AUTOSAR XML (schema 4-2-2)
package /STELLANTIS/EPT/ASWCs
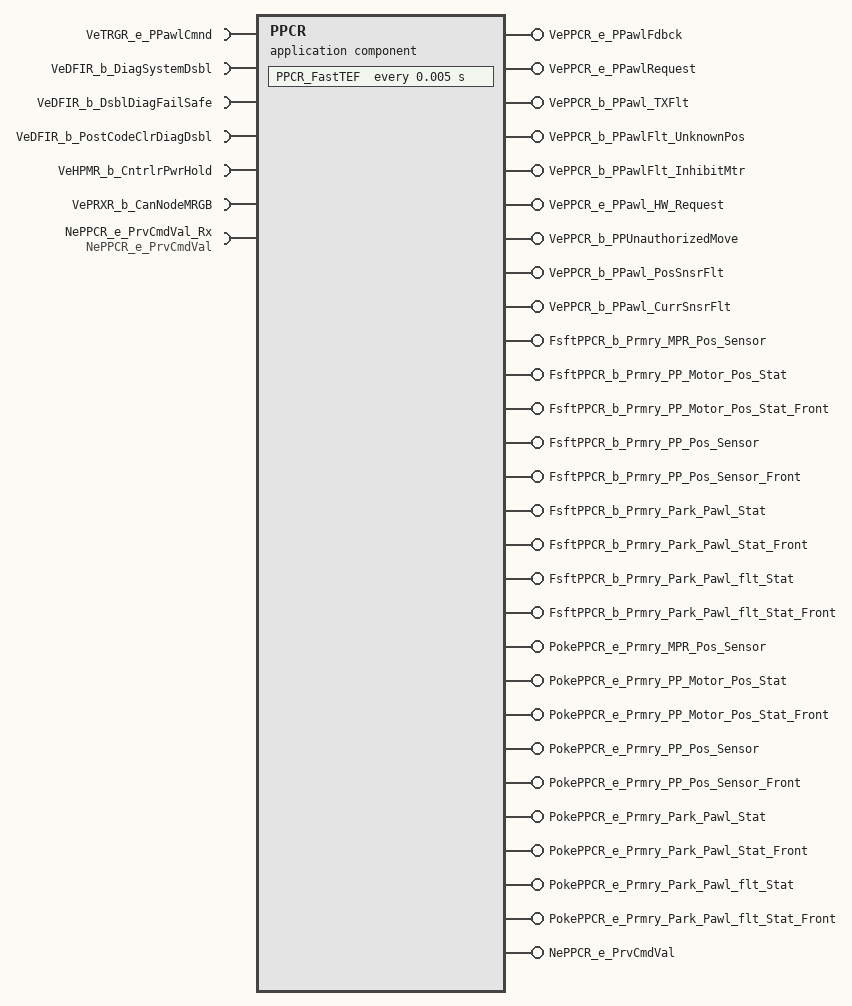
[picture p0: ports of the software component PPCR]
  application sw component type PPCR
    6 x require port:
      VeTRGR_e_PPawlCmnd: variation-point={short-label=vpVeTRGR_e_PPawlCmnd, sw-syscond=1}, nonqueued-receiver-com-spec{data-element=Value, init-value=CeTRGR_e_PPawlIdle}, required-interface=VeTRGR_e_PPawlCmnd
      VeDFIR_b_DiagSystemDsbl: variation-point={short-label=vpVeDFIR_b_DiagSystemDsbl, sw-syscond=1}, nonqueued-receiver-com-spec{data-element=Value, init-value=0}, required-interface=VeDFIR_b_DiagSystemDsbl
      VeDFIR_b_DsblDiagFailSafe: variation-point={short-label=vpVeDFIR_b_DsblDiagFailSafe, sw-syscond=1}, nonqueued-receiver-com-spec{data-element=Value, init-value=0}, required-interface=VeDFIR_b_DsblDiagFailSafe
      VeDFIR_b_PostCodeClrDiagDsbl: variation-point={short-label=vpVeDFIR_b_PostCodeClrDiagDsbl, sw-syscond=1}, nonqueued-receiver-com-spec{data-element=Value, init-value=0}, required-interface=VeDFIR_b_PostCodeClrDiagDsbl
      VeHPMR_b_CntrlrPwrHold: variation-point={short-label=vpVeHPMR_b_CntrlrPwrHold, sw-syscond=1}, nonqueued-receiver-com-spec{data-element=Value, init-value=0}, required-interface=VeHPMR_b_CntrlrPwrHold
      VePRXR_b_CanNodeMRGB: variation-point={short-label=vpVePRXR_b_CanNodeMRGB, sw-syscond=1}, nonqueued-receiver-com-spec{data-element=Value, init-value=0}, required-interface=VePRXR_b_CanNodeMRGB
    27 x provide port:
      VePPCR_e_PPawlFdbck: nonqueued-sender-com-spec{data-element=Value, init-value=CePPCR_e_PPAWL_UNKNOWN_Position}, provided-interface=VePPCR_e_PPawlFdbck
      VePPCR_e_PPawlRequest: nonqueued-sender-com-spec{data-element=Value, init-value=CePPCR_e_PPAWL_UNKNOWN_Request}, provided-interface=VePPCR_e_PPawlRequest
      VePPCR_b_PPawl_TXFlt: nonqueued-sender-com-spec{data-element=Value, init-value=0}, provided-interface=VePPCR_b_PPawl_TXFlt
      VePPCR_b_PPawlFlt_UnknownPos: nonqueued-sender-com-spec{data-element=Value, init-value=0}, provided-interface=VePPCR_b_PPawlFlt_UnknownPos
      VePPCR_b_PPawlFlt_InhibitMtr: nonqueued-sender-com-spec{data-element=Value, init-value=0}, provided-interface=VePPCR_b_PPawlFlt_InhibitMtr
      VePPCR_e_PPawl_HW_Request: nonqueued-sender-com-spec{data-element=Value, init-value=CePPCR_e_Req_No_Req}, provided-interface=VePPCR_e_PPawl_HW_Request
      VePPCR_b_PPUnauthorizedMove: nonqueued-sender-com-spec{data-element=Value, init-value=0}, provided-interface=VePPCR_b_PPUnauthorizedMove
      VePPCR_b_PPawl_PosSnsrFlt: nonqueued-sender-com-spec{data-element=Value, init-value=0}, provided-interface=VePPCR_b_PPawl_PosSnsrFlt
      VePPCR_b_PPawl_CurrSnsrFlt: nonqueued-sender-com-spec{data-element=Value, init-value=0}, provided-interface=VePPCR_b_PPawl_CurrSnsrFlt
      FsftPPCR_b_Prmry_MPR_Pos_Sensor: server-com-spec=FsftPPCR_b_Prmry_MPR_Pos_Sensor, provided-interface=FsftPPCR_b_Prmry_MPR_Pos_Sensor
      FsftPPCR_b_Prmry_PP_Motor_Pos_Stat: server-com-spec=FsftPPCR_b_Prmry_PP_Motor_Pos_Stat, provided-interface=FsftPPCR_b_Prmry_PP_Motor_Pos_Stat
      FsftPPCR_b_Prmry_PP_Motor_Pos_Stat_Front: server-com-spec=FsftPPCR_b_Prmry_PP_Motor_Pos_Stat_Front, provided-interface=FsftPPCR_b_Prmry_PP_Motor_Pos_Stat_Front
      FsftPPCR_b_Prmry_PP_Pos_Sensor: server-com-spec=FsftPPCR_b_Prmry_PP_Pos_Sensor, provided-interface=FsftPPCR_b_Prmry_PP_Pos_Sensor
      FsftPPCR_b_Prmry_PP_Pos_Sensor_Front: server-com-spec=FsftPPCR_b_Prmry_PP_Pos_Sensor_Front, provided-interface=FsftPPCR_b_Prmry_PP_Pos_Sensor_Front
      FsftPPCR_b_Prmry_Park_Pawl_Stat: server-com-spec=FsftPPCR_b_Prmry_Park_Pawl_Stat, provided-interface=FsftPPCR_b_Prmry_Park_Pawl_Stat
      FsftPPCR_b_Prmry_Park_Pawl_Stat_Front: server-com-spec=FsftPPCR_b_Prmry_Park_Pawl_Stat_Front, provided-interface=FsftPPCR_b_Prmry_Park_Pawl_Stat_Front
      FsftPPCR_b_Prmry_Park_Pawl_flt_Stat: server-com-spec=FsftPPCR_b_Prmry_Park_Pawl_flt_Stat, provided-interface=FsftPPCR_b_Prmry_Park_Pawl_flt_Stat
      FsftPPCR_b_Prmry_Park_Pawl_flt_Stat_Front: server-com-spec=FsftPPCR_b_Prmry_Park_Pawl_flt_Stat_Front, provided-interface=FsftPPCR_b_Prmry_Park_Pawl_flt_Stat_Front
      PokePPCR_e_Prmry_MPR_Pos_Sensor: server-com-spec{operation=PokePPCR_e_Prmry_MPR_Pos_Sensor, queue-length=1}, provided-interface=PokePPCR_e_Prmry_MPR_Pos_Sensor
      PokePPCR_e_Prmry_PP_Motor_Pos_Stat: server-com-spec{operation=PokePPCR_e_Prmry_PP_Motor_Pos_Stat, queue-length=1}, provided-interface=PokePPCR_e_Prmry_PP_Motor_Pos_Stat
      PokePPCR_e_Prmry_PP_Motor_Pos_Stat_Front: server-com-spec{operation=PokePPCR_e_Prmry_PP_Motor_Pos_Stat_Front, queue-length=1}, provided-interface=PokePPCR_e_Prmry_PP_Motor_Pos_Stat_Front
      PokePPCR_e_Prmry_PP_Pos_Sensor: server-com-spec{operation=PokePPCR_e_Prmry_PP_Pos_Sensor, queue-length=1}, provided-interface=PokePPCR_e_Prmry_PP_Pos_Sensor
      PokePPCR_e_Prmry_PP_Pos_Sensor_Front: server-com-spec{operation=PokePPCR_e_Prmry_PP_Pos_Sensor_Front, queue-length=1}, provided-interface=PokePPCR_e_Prmry_PP_Pos_Sensor_Front
      PokePPCR_e_Prmry_Park_Pawl_Stat: server-com-spec{operation=PokePPCR_e_Prmry_Park_Pawl_Stat, queue-length=1}, provided-interface=PokePPCR_e_Prmry_Park_Pawl_Stat
      PokePPCR_e_Prmry_Park_Pawl_Stat_Front: server-com-spec{operation=PokePPCR_e_Prmry_Park_Pawl_Stat_Front, queue-length=1}, provided-interface=PokePPCR_e_Prmry_Park_Pawl_Stat_Front
      PokePPCR_e_Prmry_Park_Pawl_flt_Stat: server-com-spec{operation=PokePPCR_e_Prmry_Park_Pawl_flt_Stat, queue-length=1}, provided-interface=PokePPCR_e_Prmry_Park_Pawl_flt_Stat
      PokePPCR_e_Prmry_Park_Pawl_flt_Stat_Front: server-com-spec{operation=PokePPCR_e_Prmry_Park_Pawl_flt_Stat_Front, queue-length=1}, provided-interface=PokePPCR_e_Prmry_Park_Pawl_flt_Stat_Front
    require port NePPCR_e_PrvCmdVal_Rx: variation-point={short-label=vpNePPCR_e_PrvCmdVal_Rx, sw-syscond=1}, nv-require-com-spec{init-value=CePPCR_e_Req_Engage, variable=NePPCR_e_PrvCmdVal}, required-interface=NePPCR_e_PrvCmdVal
    provide port NePPCR_e_PrvCmdVal: variation-point={short-label=vpNePPCR_e_PrvCmdVal, sw-syscond=1}, nv-provide-com-spec{ram-block-init-value=CePPCR_e_Req_Engage, variable=NePPCR_e_PrvCmdVal}, provided-interface=NePPCR_e_PrvCmdVal
    behavior IB_PPCR: data-type-mapping=msADTtoIDTMapping, handle-termination-and-restart=NO-SUPPORT
      timing event Event_FastTEF: start-on-event=PPCR_FastTEF, period=0.005
      18 x operation invoked event:
        Event_FsftPPCR_b_Prmry_MPR_Pos_Sensor: start-on-event=FsftPPCR_b_Prmry_MPR_Pos_Sensor, operation=FsftPPCR_b_Prmry_MPR_Pos_Sensor.FsftPPCR_b_Prmry_MPR_Pos_Sensor
        Event_FsftPPCR_b_Prmry_PP_Motor_Pos_Stat: start-on-event=FsftPPCR_b_Prmry_PP_Motor_Pos_Stat, operation=FsftPPCR_b_Prmry_PP_Motor_Pos_Stat.FsftPPCR_b_Prmry_PP_Motor_Pos_Stat
        Event_FsftPPCR_b_Prmry_PP_Motor_Pos_Stat_Front: start-on-event=FsftPPCR_b_Prmry_PP_Motor_Pos_Stat_Front, operation=FsftPPCR_b_Prmry_PP_Motor_Pos_Stat_Front.FsftPPCR_b_Prmry_PP_Motor_Pos_Stat_Front
        Event_FsftPPCR_b_Prmry_PP_Pos_Sensor: start-on-event=FsftPPCR_b_Prmry_PP_Pos_Sensor, operation=FsftPPCR_b_Prmry_PP_Pos_Sensor.FsftPPCR_b_Prmry_PP_Pos_Sensor
        Event_FsftPPCR_b_Prmry_PP_Pos_Sensor_Front: start-on-event=FsftPPCR_b_Prmry_PP_Pos_Sensor_Front, operation=FsftPPCR_b_Prmry_PP_Pos_Sensor_Front.FsftPPCR_b_Prmry_PP_Pos_Sensor_Front
        Event_FsftPPCR_b_Prmry_Park_Pawl_Stat: start-on-event=FsftPPCR_b_Prmry_Park_Pawl_Stat, operation=FsftPPCR_b_Prmry_Park_Pawl_Stat.FsftPPCR_b_Prmry_Park_Pawl_Stat
        Event_FsftPPCR_b_Prmry_Park_Pawl_Stat_Front: start-on-event=FsftPPCR_b_Prmry_Park_Pawl_Stat_Front, operation=FsftPPCR_b_Prmry_Park_Pawl_Stat_Front.FsftPPCR_b_Prmry_Park_Pawl_Stat_Front
        Event_FsftPPCR_b_Prmry_Park_Pawl_flt_Stat: start-on-event=FsftPPCR_b_Prmry_Park_Pawl_flt_Stat, operation=FsftPPCR_b_Prmry_Park_Pawl_flt_Stat.FsftPPCR_b_Prmry_Park_Pawl_flt_Stat
        Event_FsftPPCR_b_Prmry_Park_Pawl_flt_Stat_Front: start-on-event=FsftPPCR_b_Prmry_Park_Pawl_flt_Stat_Front, operation=FsftPPCR_b_Prmry_Park_Pawl_flt_Stat_Front.FsftPPCR_b_Prmry_Park_Pawl_flt_Stat_Front
        Event_PokePPCR_e_Prmry_MPR_Pos_Sensor: start-on-event=PokePPCR_e_Prmry_MPR_Pos_Sensor, operation=PokePPCR_e_Prmry_MPR_Pos_Sensor.PokePPCR_e_Prmry_MPR_Pos_Sensor
        Event_PokePPCR_e_Prmry_PP_Motor_Pos_Stat: start-on-event=PokePPCR_e_Prmry_PP_Motor_Pos_Stat, operation=PokePPCR_e_Prmry_PP_Motor_Pos_Stat.PokePPCR_e_Prmry_PP_Motor_Pos_Stat
        Event_PokePPCR_e_Prmry_PP_Motor_Pos_Stat_Front: start-on-event=PokePPCR_e_Prmry_PP_Motor_Pos_Stat_Front, operation=PokePPCR_e_Prmry_PP_Motor_Pos_Stat_Front.PokePPCR_e_Prmry_PP_Motor_Pos_Stat_Front
        Event_PokePPCR_e_Prmry_PP_Pos_Sensor: start-on-event=PokePPCR_e_Prmry_PP_Pos_Sensor, operation=PokePPCR_e_Prmry_PP_Pos_Sensor.PokePPCR_e_Prmry_PP_Pos_Sensor
        Event_PokePPCR_e_Prmry_PP_Pos_Sensor_Front: start-on-event=PokePPCR_e_Prmry_PP_Pos_Sensor_Front, operation=PokePPCR_e_Prmry_PP_Pos_Sensor_Front.PokePPCR_e_Prmry_PP_Pos_Sensor_Front
        Event_PokePPCR_e_Prmry_Park_Pawl_Stat: start-on-event=PokePPCR_e_Prmry_Park_Pawl_Stat, operation=PokePPCR_e_Prmry_Park_Pawl_Stat.PokePPCR_e_Prmry_Park_Pawl_Stat
        Event_PokePPCR_e_Prmry_Park_Pawl_Stat_Front: start-on-event=PokePPCR_e_Prmry_Park_Pawl_Stat_Front, operation=PokePPCR_e_Prmry_Park_Pawl_Stat_Front.PokePPCR_e_Prmry_Park_Pawl_Stat_Front
        Event_PokePPCR_e_Prmry_Park_Pawl_flt_Stat: start-on-event=PokePPCR_e_Prmry_Park_Pawl_flt_Stat, operation=PokePPCR_e_Prmry_Park_Pawl_flt_Stat.PokePPCR_e_Prmry_Park_Pawl_flt_Stat
        Event_PokePPCR_e_Prmry_Park_Pawl_flt_Stat_Front: start-on-event=PokePPCR_e_Prmry_Park_Pawl_flt_Stat_Front, operation=PokePPCR_e_Prmry_Park_Pawl_flt_Stat_Front.PokePPCR_e_Prmry_Park_Pawl_flt_Stat_Front
      init event Event_PPCR_ac_Init: start-on-event=PPCR_ac_Init
      init event Event_PwrOn: start-on-event=PPCR_PwrOn
      init event Event_PwrOff: start-on-event=PPCR_PwrOff
      explicit-inter-runnable-variables:
        18 x data, all with category=VALUE, sw-calibration-access=READ-ONLY:
          Park_Pawl_Stat_Init_write_IRV: type=TePPCR_e_PCUCtrl_StateCode, init-value=CePPCR_e_SC_Init, variation-point={short-label=vpPark_Pawl_Stat_Init_write_IRV, sw-syscond=1}
          VePPCR_b_Prmry_Park_Pawl_StatFA_write_IRV: type=Boolean, init-value=0, variation-point={short-label=vpVePPCR_b_Prmry_Park_Pawl_StatFA_write_IRV, sw-syscond=1}
          Park_Pawl_flt_Stat_Init_write_IRV: type=TePPCR_e_PCUCtrl_Flt_Stat, init-value=CePPCR_e_FS_No_Fault, variation-point={short-label=vpPark_Pawl_flt_Stat_Init_write_IRV, sw-syscond=1}
          VePPCR_b_Prmry_Park_Pawl_flt_StatFA_write_IRV: type=Boolean, init-value=0, variation-point={short-label=vpVePPCR_b_Prmry_Park_Pawl_flt_StatFA_write_IRV, sw-syscond=1}
          PP_MotorPos_Stat_Init_write_IRV: type=TePPCR_e_PCUCtrl_MtrPosStat, init-value=CePPCR_e_Mtr_Unknown, variation-point={short-label=vpPP_MotorPos_Stat_Init_write_IRV, sw-syscond=1}
          VePPCR_b_Prmry_PP_Motor_Pos_StatFA_write_IRV: type=Boolean, init-value=0, variation-point={short-label=vpVePPCR_b_Prmry_PP_Motor_Pos_StatFA_write_IRV, sw-syscond=1}
          PP_Pos_Sensor_Init_write_IRV: type=TePPCR_e_PCUCtrl_PosSnsr, init-value=CePPCR_e_PosSnsr_Unknown, variation-point={short-label=vpPP_Pos_Sensor_Init_write_IRV, sw-syscond=1}
          VePPCR_b_Prmry_PP_Pos_SensorFA_write_IRV: type=Boolean, init-value=0, variation-point={short-label=vpVePPCR_b_Prmry_PP_Pos_SensorFA_write_IRV, sw-syscond=1}
          MPR_Pos_Sensor_Init_write_IRV: type=TePPCR_e_PCUCtrl_MPR_Pos, init-value=CePPCR_e_MPR_Init, variation-point={short-label=vpMPR_Pos_Sensor_Init_write_IRV, sw-syscond=1}
          VePPCR_b_Prmry_MPR_Pos_SensorFA_write_IRV: type=Boolean, init-value=0, variation-point={short-label=vpVePPCR_b_Prmry_MPR_Pos_SensorFA_write_IRV, sw-syscond=1}
          VePPCR_b_Prmry_Park_Pawl_StatFA_Front_write_IRV: type=Boolean, init-value=0, variation-point={short-label=vpVePPCR_b_Prmry_Park_Pawl_StatFA_Front_write_IRV, sw-syscond=1}
          VePPCR_b_Prmry_Park_Pawl_flt_StatFA_Front_write_IRV: type=Boolean, init-value=0, variation-point={short-label=vpVePPCR_b_Prmry_Park_Pawl_flt_StatFA_Front_write_IRV, sw-syscond=1}
          VePPCR_b_Prmry_PP_Motor_Pos_StatFA_Front_write_IRV: type=Boolean, init-value=0, variation-point={short-label=vpVePPCR_b_Prmry_PP_Motor_Pos_StatFA_Front_write_IRV, sw-syscond=1}
          VePPCR_b_Prmry_PP_Pos_SensorFA_Front_write_IRV: type=Boolean, init-value=0, variation-point={short-label=vpVePPCR_b_Prmry_PP_Pos_SensorFA_Front_write_IRV, sw-syscond=1}
          Park_Pawl_Stat_Init_Front_write_IRV: type=TePPCR_e_PCUCtrl_StateCode, init-value=CePPCR_e_SC_Init, variation-point={short-label=vpPark_Pawl_Stat_Init_Front_write_IRV, sw-syscond=1}
          Park_Pawl_flt_Stat_Init_Front_write_IRV: type=TePPCR_e_PCUCtrl_Flt_Stat, init-value=CePPCR_e_FS_No_Fault, variation-point={short-label=vpPark_Pawl_flt_Stat_Init_Front_write_IRV, sw-syscond=1}
          PP_MotorPos_Stat_Init_Front_write_IRV: type=TePPCR_e_PCUCtrl_MtrPosStat, init-value=CePPCR_e_Mtr_Unknown, variation-point={short-label=vpPP_MotorPos_Stat_Init_Front_write_IRV, sw-syscond=1}
          PP_Pos_Sensor_Init_Front_write_IRV: type=TePPCR_e_PCUCtrl_PosSnsr, init-value=CePPCR_e_PosSnsr_Unknown, variation-point={short-label=vpPP_Pos_Sensor_Init_Front_write_IRV, sw-syscond=1}
      22 x runnable:
        PPCR_ac_Init
          data-send-points:
            6 x access:
              OUT_VePPCR_b_PPUnauthorizedMove_Value: accessed-variable=VePPCR_b_PPUnauthorizedMove.Value
              OUT_VePPCR_b_PPawl_PosSnsrFlt_Value: accessed-variable=VePPCR_b_PPawl_PosSnsrFlt.Value
              OUT_VePPCR_b_PPawl_CurrSnsrFlt_Value: accessed-variable=VePPCR_b_PPawl_CurrSnsrFlt.Value
              OUT_VePPCR_e_PPawlFdbck_Value: accessed-variable=VePPCR_e_PPawlFdbck.Value
              OUT_VePPCR_e_PPawlRequest_Value: accessed-variable=VePPCR_e_PPawlRequest.Value
              OUT_VePPCR_e_PPawl_HW_Request_Value: accessed-variable=VePPCR_e_PPawl_HW_Request.Value
        PPCR_PwrOn
          data-receive-point-by-arguments:
            access IN_NePPCR_e_PrvCmdVal_Rx_NePPCR_e_PrvCmdVal: accessed-variable=NePPCR_e_PrvCmdVal_Rx.NePPCR_e_PrvCmdVal, variation-point={short-label=vpIN_NePPCR_e_PrvCmdVal_Rx_NePPCR_e_PrvCmdVal, sw-syscond=1}
          data-send-points:
            9 x access:
              OUT_VePPCR_e_PPawlFdbck_Value: accessed-variable=VePPCR_e_PPawlFdbck.Value
              OUT_VePPCR_e_PPawlRequest_Value: accessed-variable=VePPCR_e_PPawlRequest.Value
              OUT_VePPCR_b_PPawl_TXFlt_Value: accessed-variable=VePPCR_b_PPawl_TXFlt.Value
              OUT_VePPCR_b_PPawlFlt_UnknownPos_Value: accessed-variable=VePPCR_b_PPawlFlt_UnknownPos.Value
              OUT_VePPCR_b_PPawlFlt_InhibitMtr_Value: accessed-variable=VePPCR_b_PPawlFlt_InhibitMtr.Value
              OUT_VePPCR_e_PPawl_HW_Request_Value: accessed-variable=VePPCR_e_PPawl_HW_Request.Value
              OUT_VePPCR_b_PPUnauthorizedMove_Value: accessed-variable=VePPCR_b_PPUnauthorizedMove.Value
              OUT_VePPCR_b_PPawl_PosSnsrFlt_Value: accessed-variable=VePPCR_b_PPawl_PosSnsrFlt.Value
              OUT_VePPCR_b_PPawl_CurrSnsrFlt_Value: accessed-variable=VePPCR_b_PPawl_CurrSnsrFlt.Value
          written-local-variables:
            18 x access:
              WV_VePPCR_b_Prmry_MPR_Pos_SensorFA_write_IRV: accessed-variable=VePPCR_b_Prmry_MPR_Pos_SensorFA_write_IRV, variation-point={short-label=vpWV_VePPCR_b_Prmry_MPR_Pos_SensorFA_write_IRV, sw-syscond=1}
              WV_MPR_Pos_Sensor_Init_write_IRV: accessed-variable=MPR_Pos_Sensor_Init_write_IRV, variation-point={short-label=vpWV_MPR_Pos_Sensor_Init_write_IRV, sw-syscond=1}
              WV_VePPCR_b_Prmry_PP_Motor_Pos_StatFA_Front_write_IRV: accessed-variable=VePPCR_b_Prmry_PP_Motor_Pos_StatFA_Front_write_IRV, variation-point={short-label=vpWV_VePPCR_b_Prmry_PP_Motor_Pos_StatFA_Front_write_IRV, sw-syscond=1}
              WV_VePPCR_b_Prmry_PP_Motor_Pos_StatFA_write_IRV: accessed-variable=VePPCR_b_Prmry_PP_Motor_Pos_StatFA_write_IRV, variation-point={short-label=vpWV_VePPCR_b_Prmry_PP_Motor_Pos_StatFA_write_IRV, sw-syscond=1}
              WV_PP_MotorPos_Stat_Init_Front_write_IRV: accessed-variable=PP_MotorPos_Stat_Init_Front_write_IRV, variation-point={short-label=vpWV_PP_MotorPos_Stat_Init_Front_write_IRV, sw-syscond=1}
              WV_PP_MotorPos_Stat_Init_write_IRV: accessed-variable=PP_MotorPos_Stat_Init_write_IRV, variation-point={short-label=vpWV_PP_MotorPos_Stat_Init_write_IRV, sw-syscond=1}
              WV_VePPCR_b_Prmry_PP_Pos_SensorFA_Front_write_IRV: accessed-variable=VePPCR_b_Prmry_PP_Pos_SensorFA_Front_write_IRV, variation-point={short-label=vpWV_VePPCR_b_Prmry_PP_Pos_SensorFA_Front_write_IRV, sw-syscond=1}
              WV_VePPCR_b_Prmry_PP_Pos_SensorFA_write_IRV: accessed-variable=VePPCR_b_Prmry_PP_Pos_SensorFA_write_IRV, variation-point={short-label=vpWV_VePPCR_b_Prmry_PP_Pos_SensorFA_write_IRV, sw-syscond=1}
              WV_PP_Pos_Sensor_Init_Front_write_IRV: accessed-variable=PP_Pos_Sensor_Init_Front_write_IRV, variation-point={short-label=vpWV_PP_Pos_Sensor_Init_Front_write_IRV, sw-syscond=1}
              WV_PP_Pos_Sensor_Init_write_IRV: accessed-variable=PP_Pos_Sensor_Init_write_IRV, variation-point={short-label=vpWV_PP_Pos_Sensor_Init_write_IRV, sw-syscond=1}
              WV_VePPCR_b_Prmry_Park_Pawl_StatFA_Front_write_IRV: accessed-variable=VePPCR_b_Prmry_Park_Pawl_StatFA_Front_write_IRV, variation-point={short-label=vpWV_VePPCR_b_Prmry_Park_Pawl_StatFA_Front_write_IRV, sw-syscond=1}
              WV_VePPCR_b_Prmry_Park_Pawl_StatFA_write_IRV: accessed-variable=VePPCR_b_Prmry_Park_Pawl_StatFA_write_IRV, variation-point={short-label=vpWV_VePPCR_b_Prmry_Park_Pawl_StatFA_write_IRV, sw-syscond=1}
              WV_Park_Pawl_Stat_Init_Front_write_IRV: accessed-variable=Park_Pawl_Stat_Init_Front_write_IRV, variation-point={short-label=vpWV_Park_Pawl_Stat_Init_Front_write_IRV, sw-syscond=1}
              WV_Park_Pawl_Stat_Init_write_IRV: accessed-variable=Park_Pawl_Stat_Init_write_IRV, variation-point={short-label=vpWV_Park_Pawl_Stat_Init_write_IRV, sw-syscond=1}
              WV_VePPCR_b_Prmry_Park_Pawl_flt_StatFA_Front_write_IRV: accessed-variable=VePPCR_b_Prmry_Park_Pawl_flt_StatFA_Front_write_IRV, variation-point={short-label=vpWV_VePPCR_b_Prmry_Park_Pawl_flt_StatFA_Front_write_IRV, sw-syscond=1}
              WV_VePPCR_b_Prmry_Park_Pawl_flt_StatFA_write_IRV: accessed-variable=VePPCR_b_Prmry_Park_Pawl_flt_StatFA_write_IRV, variation-point={short-label=vpWV_VePPCR_b_Prmry_Park_Pawl_flt_StatFA_write_IRV, sw-syscond=1}
              WV_Park_Pawl_flt_Stat_Init_Front_write_IRV: accessed-variable=Park_Pawl_flt_Stat_Init_Front_write_IRV, variation-point={short-label=vpWV_Park_Pawl_flt_Stat_Init_Front_write_IRV, sw-syscond=1}
              WV_Park_Pawl_flt_Stat_Init_write_IRV: accessed-variable=Park_Pawl_flt_Stat_Init_write_IRV, variation-point={short-label=vpWV_Park_Pawl_flt_Stat_Init_write_IRV, sw-syscond=1}
        PPCR_FastTEF: variation-point={short-label=vpPPCR_FastTEF, sw-syscond=1}
          data-receive-point-by-arguments:
            6 x access:
              IN_VeDFIR_b_DiagSystemDsbl_Value: accessed-variable=VeDFIR_b_DiagSystemDsbl.Value, variation-point={short-label=vpIN_VeDFIR_b_DiagSystemDsbl_Value, sw-syscond=1}
              IN_VeDFIR_b_DsblDiagFailSafe_Value: accessed-variable=VeDFIR_b_DsblDiagFailSafe.Value, variation-point={short-label=vpIN_VeDFIR_b_DsblDiagFailSafe_Value, sw-syscond=1}
              IN_VeDFIR_b_PostCodeClrDiagDsbl_Value: accessed-variable=VeDFIR_b_PostCodeClrDiagDsbl.Value, variation-point={short-label=vpIN_VeDFIR_b_PostCodeClrDiagDsbl_Value, sw-syscond=1}
              IN_VeHPMR_b_CntrlrPwrHold_Value: accessed-variable=VeHPMR_b_CntrlrPwrHold.Value, variation-point={short-label=vpIN_VeHPMR_b_CntrlrPwrHold_Value, sw-syscond=1}
              IN_VePRXR_b_CanNodeMRGB_Value: accessed-variable=VePRXR_b_CanNodeMRGB.Value, variation-point={short-label=vpIN_VePRXR_b_CanNodeMRGB_Value, sw-syscond=1}
              IN_VeTRGR_e_PPawlCmnd_Value: accessed-variable=VeTRGR_e_PPawlCmnd.Value, variation-point={short-label=vpIN_VeTRGR_e_PPawlCmnd_Value, sw-syscond=1}
          data-send-points:
            6 x access:
              OUT_VePPCR_e_PPawl_HW_Request_Value: accessed-variable=VePPCR_e_PPawl_HW_Request.Value
              OUT_VePPCR_e_PPawlFdbck_Value: accessed-variable=VePPCR_e_PPawlFdbck.Value
              OUT_VePPCR_e_PPawlRequest_Value: accessed-variable=VePPCR_e_PPawlRequest.Value
              OUT_VePPCR_b_PPawl_TXFlt_Value: accessed-variable=VePPCR_b_PPawl_TXFlt.Value
              OUT_VePPCR_b_PPawlFlt_UnknownPos_Value: accessed-variable=VePPCR_b_PPawlFlt_UnknownPos.Value
              OUT_VePPCR_b_PPawlFlt_InhibitMtr_Value: accessed-variable=VePPCR_b_PPawlFlt_InhibitMtr.Value
          read-local-variables:
            18 x access:
              RV_MPR_Pos_Sensor_Init_write_IRV: accessed-variable=MPR_Pos_Sensor_Init_write_IRV, variation-point={short-label=vpRV_MPR_Pos_Sensor_Init_write_IRV, sw-syscond=1}
              RV_PP_MotorPos_Stat_Init_Front_write_IRV: accessed-variable=PP_MotorPos_Stat_Init_Front_write_IRV, variation-point={short-label=vpRV_PP_MotorPos_Stat_Init_Front_write_IRV, sw-syscond=1}
              RV_PP_MotorPos_Stat_Init_write_IRV: accessed-variable=PP_MotorPos_Stat_Init_write_IRV, variation-point={short-label=vpRV_PP_MotorPos_Stat_Init_write_IRV, sw-syscond=1}
              RV_PP_Pos_Sensor_Init_Front_write_IRV: accessed-variable=PP_Pos_Sensor_Init_Front_write_IRV, variation-point={short-label=vpRV_PP_Pos_Sensor_Init_Front_write_IRV, sw-syscond=1}
              RV_PP_Pos_Sensor_Init_write_IRV: accessed-variable=PP_Pos_Sensor_Init_write_IRV, variation-point={short-label=vpRV_PP_Pos_Sensor_Init_write_IRV, sw-syscond=1}
              RV_Park_Pawl_Stat_Init_Front_write_IRV: accessed-variable=Park_Pawl_Stat_Init_Front_write_IRV, variation-point={short-label=vpRV_Park_Pawl_Stat_Init_Front_write_IRV, sw-syscond=1}
              RV_Park_Pawl_Stat_Init_write_IRV: accessed-variable=Park_Pawl_Stat_Init_write_IRV, variation-point={short-label=vpRV_Park_Pawl_Stat_Init_write_IRV, sw-syscond=1}
              RV_Park_Pawl_flt_Stat_Init_Front_write_IRV: accessed-variable=Park_Pawl_flt_Stat_Init_Front_write_IRV, variation-point={short-label=vpRV_Park_Pawl_flt_Stat_Init_Front_write_IRV, sw-syscond=1}
              RV_Park_Pawl_flt_Stat_Init_write_IRV: accessed-variable=Park_Pawl_flt_Stat_Init_write_IRV, variation-point={short-label=vpRV_Park_Pawl_flt_Stat_Init_write_IRV, sw-syscond=1}
              RV_VePPCR_b_Prmry_MPR_Pos_SensorFA_write_IRV: accessed-variable=VePPCR_b_Prmry_MPR_Pos_SensorFA_write_IRV, variation-point={short-label=vpRV_VePPCR_b_Prmry_MPR_Pos_SensorFA_write_IRV, sw-syscond=1}
              RV_VePPCR_b_Prmry_PP_Motor_Pos_StatFA_Front_write_IRV: accessed-variable=VePPCR_b_Prmry_PP_Motor_Pos_StatFA_Front_write_IRV, variation-point={short-label=vpRV_VePPCR_b_Prmry_PP_Motor_Pos_StatFA_Front_write_IRV, sw-syscond=1}
              RV_VePPCR_b_Prmry_PP_Motor_Pos_StatFA_write_IRV: accessed-variable=VePPCR_b_Prmry_PP_Motor_Pos_StatFA_write_IRV, variation-point={short-label=vpRV_VePPCR_b_Prmry_PP_Motor_Pos_StatFA_write_IRV, sw-syscond=1}
              RV_VePPCR_b_Prmry_PP_Pos_SensorFA_Front_write_IRV: accessed-variable=VePPCR_b_Prmry_PP_Pos_SensorFA_Front_write_IRV, variation-point={short-label=vpRV_VePPCR_b_Prmry_PP_Pos_SensorFA_Front_write_IRV, sw-syscond=1}
              RV_VePPCR_b_Prmry_PP_Pos_SensorFA_write_IRV: accessed-variable=VePPCR_b_Prmry_PP_Pos_SensorFA_write_IRV, variation-point={short-label=vpRV_VePPCR_b_Prmry_PP_Pos_SensorFA_write_IRV, sw-syscond=1}
              RV_VePPCR_b_Prmry_Park_Pawl_StatFA_Front_write_IRV: accessed-variable=VePPCR_b_Prmry_Park_Pawl_StatFA_Front_write_IRV, variation-point={short-label=vpRV_VePPCR_b_Prmry_Park_Pawl_StatFA_Front_write_IRV, sw-syscond=1}
              RV_VePPCR_b_Prmry_Park_Pawl_StatFA_write_IRV: accessed-variable=VePPCR_b_Prmry_Park_Pawl_StatFA_write_IRV, variation-point={short-label=vpRV_VePPCR_b_Prmry_Park_Pawl_StatFA_write_IRV, sw-syscond=1}
              RV_VePPCR_b_Prmry_Park_Pawl_flt_StatFA_Front_write_IRV: accessed-variable=VePPCR_b_Prmry_Park_Pawl_flt_StatFA_Front_write_IRV, variation-point={short-label=vpRV_VePPCR_b_Prmry_Park_Pawl_flt_StatFA_Front_write_IRV, sw-syscond=1}
              RV_VePPCR_b_Prmry_Park_Pawl_flt_StatFA_write_IRV: accessed-variable=VePPCR_b_Prmry_Park_Pawl_flt_StatFA_write_IRV, variation-point={short-label=vpRV_VePPCR_b_Prmry_Park_Pawl_flt_StatFA_write_IRV, sw-syscond=1}
        PPCR_PwrOff: variation-point={short-label=vpPPCR_PwrOff, sw-syscond=1}
          data-send-points:
            access OUT_NePPCR_e_PrvCmdVal_NePPCR_e_PrvCmdVal: accessed-variable=NePPCR_e_PrvCmdVal.NePPCR_e_PrvCmdVal, variation-point={short-label=vpOUT_NePPCR_e_PrvCmdVal_NePPCR_e_PrvCmdVal, sw-syscond=1}
        FsftPPCR_b_Prmry_MPR_Pos_Sensor: variation-point={short-label=vpFsftPPCR_b_Prmry_MPR_Pos_Sensor, sw-syscond=1}
          written-local-variables:
            access WV_VePPCR_b_Prmry_MPR_Pos_SensorFA_write_IRV: accessed-variable=VePPCR_b_Prmry_MPR_Pos_SensorFA_write_IRV, variation-point={short-label=vpWV_VePPCR_b_Prmry_MPR_Pos_SensorFA_write_IRV, sw-syscond=1}
        FsftPPCR_b_Prmry_PP_Motor_Pos_Stat: variation-point={short-label=vpFsftPPCR_b_Prmry_PP_Motor_Pos_Stat, sw-syscond=1}
          written-local-variables:
            access WV_VePPCR_b_Prmry_PP_Motor_Pos_StatFA_write_IRV: accessed-variable=VePPCR_b_Prmry_PP_Motor_Pos_StatFA_write_IRV, variation-point={short-label=vpWV_VePPCR_b_Prmry_PP_Motor_Pos_StatFA_write_IRV, sw-syscond=1}
        FsftPPCR_b_Prmry_PP_Motor_Pos_Stat_Front: variation-point={short-label=vpFsftPPCR_b_Prmry_PP_Motor_Pos_Stat_Front, sw-syscond=1}
          written-local-variables:
            access WV_VePPCR_b_Prmry_PP_Motor_Pos_StatFA_Front_write_IRV: accessed-variable=VePPCR_b_Prmry_PP_Motor_Pos_StatFA_Front_write_IRV, variation-point={short-label=vpWV_VePPCR_b_Prmry_PP_Motor_Pos_StatFA_Front_write_IRV, sw-syscond=1}
        FsftPPCR_b_Prmry_PP_Pos_Sensor: variation-point={short-label=vpFsftPPCR_b_Prmry_PP_Pos_Sensor, sw-syscond=1}
          written-local-variables:
            access WV_VePPCR_b_Prmry_PP_Pos_SensorFA_write_IRV: accessed-variable=VePPCR_b_Prmry_PP_Pos_SensorFA_write_IRV, variation-point={short-label=vpWV_VePPCR_b_Prmry_PP_Pos_SensorFA_write_IRV, sw-syscond=1}
        FsftPPCR_b_Prmry_PP_Pos_Sensor_Front: variation-point={short-label=vpFsftPPCR_b_Prmry_PP_Pos_Sensor_Front, sw-syscond=1}
          written-local-variables:
            access WV_VePPCR_b_Prmry_PP_Pos_SensorFA_Front_write_IRV: accessed-variable=VePPCR_b_Prmry_PP_Pos_SensorFA_Front_write_IRV, variation-point={short-label=vpWV_VePPCR_b_Prmry_PP_Pos_SensorFA_Front_write_IRV, sw-syscond=1}
        FsftPPCR_b_Prmry_Park_Pawl_Stat: variation-point={short-label=vpFsftPPCR_b_Prmry_Park_Pawl_Stat, sw-syscond=1}
          written-local-variables:
            access WV_VePPCR_b_Prmry_Park_Pawl_StatFA_write_IRV: accessed-variable=VePPCR_b_Prmry_Park_Pawl_StatFA_write_IRV, variation-point={short-label=vpWV_VePPCR_b_Prmry_Park_Pawl_StatFA_write_IRV, sw-syscond=1}
        FsftPPCR_b_Prmry_Park_Pawl_Stat_Front: variation-point={short-label=vpFsftPPCR_b_Prmry_Park_Pawl_Stat_Front, sw-syscond=1}
          written-local-variables:
            access WV_VePPCR_b_Prmry_Park_Pawl_StatFA_Front_write_IRV: accessed-variable=VePPCR_b_Prmry_Park_Pawl_StatFA_Front_write_IRV, variation-point={short-label=vpWV_VePPCR_b_Prmry_Park_Pawl_StatFA_Front_write_IRV, sw-syscond=1}
        FsftPPCR_b_Prmry_Park_Pawl_flt_Stat: variation-point={short-label=vpFsftPPCR_b_Prmry_Park_Pawl_flt_Stat, sw-syscond=1}
          written-local-variables:
            access WV_VePPCR_b_Prmry_Park_Pawl_flt_StatFA_write_IRV: accessed-variable=VePPCR_b_Prmry_Park_Pawl_flt_StatFA_write_IRV, variation-point={short-label=vpWV_VePPCR_b_Prmry_Park_Pawl_flt_StatFA_write_IRV, sw-syscond=1}
        FsftPPCR_b_Prmry_Park_Pawl_flt_Stat_Front: variation-point={short-label=vpFsftPPCR_b_Prmry_Park_Pawl_flt_Stat_Front, sw-syscond=1}
          written-local-variables:
            access WV_VePPCR_b_Prmry_Park_Pawl_flt_StatFA_Front_write_IRV: accessed-variable=VePPCR_b_Prmry_Park_Pawl_flt_StatFA_Front_write_IRV, variation-point={short-label=vpWV_VePPCR_b_Prmry_Park_Pawl_flt_StatFA_Front_write_IRV, sw-syscond=1}
        PokePPCR_e_Prmry_MPR_Pos_Sensor: variation-point={short-label=vpPokePPCR_e_Prmry_MPR_Pos_Sensor, sw-syscond=1}
          written-local-variables:
            access WV_VePPCR_b_Prmry_MPR_Pos_SensorFA_write_IRV: accessed-variable=VePPCR_b_Prmry_MPR_Pos_SensorFA_write_IRV, variation-point={short-label=vpWV_VePPCR_b_Prmry_MPR_Pos_SensorFA_write_IRV, sw-syscond=1}
            access WV_MPR_Pos_Sensor_Init_write_IRV: accessed-variable=MPR_Pos_Sensor_Init_write_IRV, variation-point={short-label=vpWV_MPR_Pos_Sensor_Init_write_IRV, sw-syscond=1}
        PokePPCR_e_Prmry_PP_Motor_Pos_Stat: variation-point={short-label=vpPokePPCR_e_Prmry_PP_Motor_Pos_Stat, sw-syscond=1}
          written-local-variables:
            access WV_VePPCR_b_Prmry_PP_Motor_Pos_StatFA_write_IRV: accessed-variable=VePPCR_b_Prmry_PP_Motor_Pos_StatFA_write_IRV, variation-point={short-label=vpWV_VePPCR_b_Prmry_PP_Motor_Pos_StatFA_write_IRV, sw-syscond=1}
            access WV_PP_MotorPos_Stat_Init_write_IRV: accessed-variable=PP_MotorPos_Stat_Init_write_IRV, variation-point={short-label=vpWV_PP_MotorPos_Stat_Init_write_IRV, sw-syscond=1}
        PokePPCR_e_Prmry_PP_Motor_Pos_Stat_Front: variation-point={short-label=vpPokePPCR_e_Prmry_PP_Motor_Pos_Stat_Front, sw-syscond=1}
          written-local-variables:
            access WV_VePPCR_b_Prmry_PP_Motor_Pos_StatFA_Front_write_IRV: accessed-variable=VePPCR_b_Prmry_PP_Motor_Pos_StatFA_Front_write_IRV, variation-point={short-label=vpWV_VePPCR_b_Prmry_PP_Motor_Pos_StatFA_Front_write_IRV, sw-syscond=1}
            access WV_PP_MotorPos_Stat_Init_Front_write_IRV: accessed-variable=PP_MotorPos_Stat_Init_Front_write_IRV, variation-point={short-label=vpWV_PP_MotorPos_Stat_Init_Front_write_IRV, sw-syscond=1}
        PokePPCR_e_Prmry_PP_Pos_Sensor: variation-point={short-label=vpPokePPCR_e_Prmry_PP_Pos_Sensor, sw-syscond=1}
          written-local-variables:
            access WV_VePPCR_b_Prmry_PP_Pos_SensorFA_write_IRV: accessed-variable=VePPCR_b_Prmry_PP_Pos_SensorFA_write_IRV, variation-point={short-label=vpWV_VePPCR_b_Prmry_PP_Pos_SensorFA_write_IRV, sw-syscond=1}
            access WV_PP_Pos_Sensor_Init_write_IRV: accessed-variable=PP_Pos_Sensor_Init_write_IRV, variation-point={short-label=vpWV_PP_Pos_Sensor_Init_write_IRV, sw-syscond=1}
        PokePPCR_e_Prmry_PP_Pos_Sensor_Front: variation-point={short-label=vpPokePPCR_e_Prmry_PP_Pos_Sensor_Front, sw-syscond=1}
          written-local-variables:
            access WV_VePPCR_b_Prmry_PP_Pos_SensorFA_Front_write_IRV: accessed-variable=VePPCR_b_Prmry_PP_Pos_SensorFA_Front_write_IRV, variation-point={short-label=vpWV_VePPCR_b_Prmry_PP_Pos_SensorFA_Front_write_IRV, sw-syscond=1}
            access WV_PP_Pos_Sensor_Init_Front_write_IRV: accessed-variable=PP_Pos_Sensor_Init_Front_write_IRV, variation-point={short-label=vpWV_PP_Pos_Sensor_Init_Front_write_IRV, sw-syscond=1}
        PokePPCR_e_Prmry_Park_Pawl_Stat: variation-point={short-label=vpPokePPCR_e_Prmry_Park_Pawl_Stat, sw-syscond=1}
          written-local-variables:
            access WV_VePPCR_b_Prmry_Park_Pawl_StatFA_write_IRV: accessed-variable=VePPCR_b_Prmry_Park_Pawl_StatFA_write_IRV, variation-point={short-label=vpWV_VePPCR_b_Prmry_Park_Pawl_StatFA_write_IRV, sw-syscond=1}
            access WV_Park_Pawl_Stat_Init_write_IRV: accessed-variable=Park_Pawl_Stat_Init_write_IRV, variation-point={short-label=vpWV_Park_Pawl_Stat_Init_write_IRV, sw-syscond=1}
        PokePPCR_e_Prmry_Park_Pawl_Stat_Front: variation-point={short-label=vpPokePPCR_e_Prmry_Park_Pawl_Stat_Front, sw-syscond=1}
          written-local-variables:
            access WV_VePPCR_b_Prmry_Park_Pawl_StatFA_Front_write_IRV: accessed-variable=VePPCR_b_Prmry_Park_Pawl_StatFA_Front_write_IRV, variation-point={short-label=vpWV_VePPCR_b_Prmry_Park_Pawl_StatFA_Front_write_IRV, sw-syscond=1}
            access WV_Park_Pawl_Stat_Init_Front_write_IRV: accessed-variable=Park_Pawl_Stat_Init_Front_write_IRV, variation-point={short-label=vpWV_Park_Pawl_Stat_Init_Front_write_IRV, sw-syscond=1}
        PokePPCR_e_Prmry_Park_Pawl_flt_Stat: variation-point={short-label=vpPokePPCR_e_Prmry_Park_Pawl_flt_Stat, sw-syscond=1}
          written-local-variables:
            access WV_VePPCR_b_Prmry_Park_Pawl_flt_StatFA_write_IRV: accessed-variable=VePPCR_b_Prmry_Park_Pawl_flt_StatFA_write_IRV, variation-point={short-label=vpWV_VePPCR_b_Prmry_Park_Pawl_flt_StatFA_write_IRV, sw-syscond=1}
            access WV_Park_Pawl_flt_Stat_Init_write_IRV: accessed-variable=Park_Pawl_flt_Stat_Init_write_IRV, variation-point={short-label=vpWV_Park_Pawl_flt_Stat_Init_write_IRV, sw-syscond=1}
        PokePPCR_e_Prmry_Park_Pawl_flt_Stat_Front: variation-point={short-label=vpPokePPCR_e_Prmry_Park_Pawl_flt_Stat_Front, sw-syscond=1}
          written-local-variables:
            access WV_VePPCR_b_Prmry_Park_Pawl_flt_StatFA_Front_write_IRV: accessed-variable=VePPCR_b_Prmry_Park_Pawl_flt_StatFA_Front_write_IRV, variation-point={short-label=vpWV_VePPCR_b_Prmry_Park_Pawl_flt_StatFA_Front_write_IRV, sw-syscond=1}
            access WV_Park_Pawl_flt_Stat_Init_Front_write_IRV: accessed-variable=Park_Pawl_flt_Stat_Init_Front_write_IRV, variation-point={short-label=vpWV_Park_Pawl_flt_Stat_Init_Front_write_IRV, sw-syscond=1}
      variation point proxy Variant_PPCR_FUNC_Enab: category=CONDITION, condition-access=1
